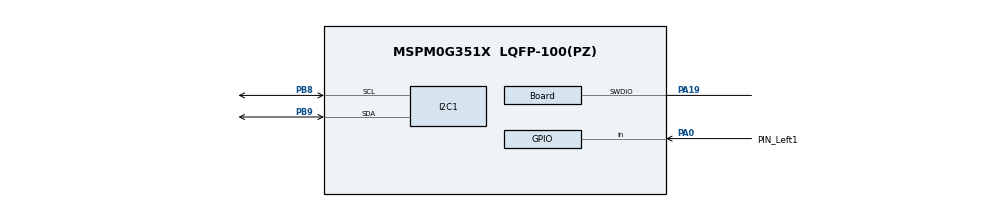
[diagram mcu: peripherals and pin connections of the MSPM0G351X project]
/**
 * @cliArgs --device "MSPM0G351X" --part "Default" --package "LQFP-100(PZ)" --product "mspm0_sdk@2.06.00.05"
 * @versions {"tool":"1.25.0+4268"}
 */

/**
 * Import the modules used in this configuration.
 */
const Board  = scripting.addModule("/ti/driverlib/Board");
const GPIO   = scripting.addModule("/ti/driverlib/GPIO", {}, false);
const GPIO1  = GPIO.addInstance();
const GPIO2  = GPIO.addInstance();
const I2C    = scripting.addModule("/ti/driverlib/I2C", {}, false);
const I2C1   = I2C.addInstance();
const PWM    = scripting.addModule("/ti/driverlib/PWM", {}, false);
const PWM1   = PWM.addInstance();
const QEI    = scripting.addModule("/ti/driverlib/QEI", {}, false);
const QEI1   = QEI.addInstance();
const QEI2   = QEI.addInstance();
const SYSCTL = scripting.addModule("/ti/driverlib/SYSCTL");
const TIMER  = scripting.addModule("/ti/driverlib/TIMER", {}, false);
const TIMER1 = TIMER.addInstance();
const TIMER2 = TIMER.addInstance();
const UART   = scripting.addModule("/ti/driverlib/UART", {}, false);
const UART1  = UART.addInstance();

/**
 * Write custom configuration values to the imported modules.
 */
Board.peripheral.swdioPin.$assign = "PA19";

GPIO1.$name                              = "GPIO_GraySensor";
GPIO1.port                               = "PORTA";
GPIO1.associatedPins.create(7);
GPIO1.associatedPins[0].$name            = "PIN_Left1";
GPIO1.associatedPins[0].direction        = "INPUT";
GPIO1.associatedPins[0].internalResistor = "PULL_DOWN";
GPIO1.associatedPins[0].pin.$assign      = "PA0";
GPIO1.associatedPins[1].$name            = "PIN_Left2";
GPIO1.associatedPins[1].internalResistor = "PULL_DOWN";
GPIO1.associatedPins[1].direction        = "INPUT";
GPIO1.associatedPins[2].$name            = "PIN_Left3";
GPIO1.associatedPins[2].internalResistor = "PULL_DOWN";
GPIO1.associatedPins[2].direction        = "INPUT";
GPIO1.associatedPins[3].$name            = "PIN_Left4";
GPIO1.associatedPins[3].internalResistor = "PULL_DOWN";
GPIO1.associatedPins[3].direction        = "INPUT";
GPIO1.associatedPins[4].$name            = "PIN_Left5";
GPIO1.associatedPins[4].direction        = "INPUT";
GPIO1.associatedPins[4].internalResistor = "PULL_DOWN";
GPIO1.associatedPins[5].$name            = "PIN_Left6";
GPIO1.associatedPins[5].direction        = "INPUT";
GPIO1.associatedPins[5].internalResistor = "PULL_DOWN";
GPIO1.associatedPins[6].$name            = "PIN_Left7";
GPIO1.associatedPins[6].direction        = "INPUT";
GPIO1.associatedPins[6].internalResistor = "PULL_DOWN";

GPIO2.$name                               = "GPIO_Soundsensor";
GPIO2.port                                = "PORTA";
GPIO2.associatedPins.create(2);
GPIO2.associatedPins[0].internalResistor  = "PULL_DOWN";
GPIO2.associatedPins[0].driveStrength     = "HIGH";
GPIO2.associatedPins[0].$name             = "Pin_Trig";
GPIO2.associatedPins[1].$name             = "PIN_Echo";
GPIO2.associatedPins[1].direction         = "INPUT";
GPIO2.associatedPins[1].internalResistor  = "PULL_DOWN";
GPIO2.associatedPins[1].polarity          = "RISE_FALL";
GPIO2.associatedPins[1].interruptPriority = "1";
GPIO2.associatedPins[1].interruptEn       = true;

I2C1.$name                             = "I2C_2";
I2C1.basicEnableController             = true;
I2C1.peripheral.sdaPin.$assign         = "PB9";
I2C1.peripheral.sclPin.$assign         = "PB8";
I2C1.sdaPinConfig.hideOutputInversion  = scripting.forceWrite(false);
I2C1.sdaPinConfig.onlyInternalResistor = scripting.forceWrite(false);
I2C1.sdaPinConfig.passedPeripheralType = scripting.forceWrite("Digital");
I2C1.sdaPinConfig.$name                = "ti_driverlib_gpio_GPIOPinGeneric4";
I2C1.sdaPinConfig.enableConfig         = true;
I2C1.sdaPinConfig.internalResistor     = "PULL_UP";
I2C1.sclPinConfig.hideOutputInversion  = scripting.forceWrite(false);
I2C1.sclPinConfig.onlyInternalResistor = scripting.forceWrite(false);
I2C1.sclPinConfig.passedPeripheralType = scripting.forceWrite("Digital");
I2C1.sclPinConfig.$name                = "ti_driverlib_gpio_GPIOPinGeneric5";
I2C1.sclPinConfig.enableConfig         = true;
I2C1.sclPinConfig.internalResistor     = "PULL_UP";

PWM1.$name                              = "PWM_Motor";
PWM1.clockDivider                       = 8;
PWM1.pwmMode                            = "EDGE_ALIGN_UP";
PWM1.timerStartTimer                    = true;
PWM1.ccIndex                            = [0,1,2,3];
PWM1.PWM_CHANNEL_0.$name                = "ti_driverlib_pwm_PWMTimerCC0";
PWM1.PWM_CHANNEL_0.shadowUpdateMode     = "COMP_DN_EVT";
PWM1.PWM_CHANNEL_1.$name                = "ti_driverlib_pwm_PWMTimerCC1";
PWM1.PWM_CHANNEL_1.shadowUpdateMode     = "COMP_DN_EVT";
PWM1.ccp0PinConfig.direction            = scripting.forceWrite("OUTPUT");
PWM1.ccp0PinConfig.hideOutputInversion  = scripting.forceWrite(false);
PWM1.ccp0PinConfig.onlyInternalResistor = scripting.forceWrite(false);
PWM1.ccp0PinConfig.passedPeripheralType = scripting.forceWrite("Digital");
PWM1.ccp0PinConfig.$name                = "ti_driverlib_gpio_GPIOPinGeneric0";
PWM1.ccp1PinConfig.direction            = scripting.forceWrite("OUTPUT");
PWM1.ccp1PinConfig.hideOutputInversion  = scripting.forceWrite(false);
PWM1.ccp1PinConfig.onlyInternalResistor = scripting.forceWrite(false);
PWM1.ccp1PinConfig.passedPeripheralType = scripting.forceWrite("Digital");
PWM1.ccp1PinConfig.$name                = "ti_driverlib_gpio_GPIOPinGeneric1";
PWM1.peripheral.$assign                 = "TIMA0";
PWM1.PWM_CHANNEL_2.$name                = "ti_driverlib_pwm_PWMTimerCC2";
PWM1.PWM_CHANNEL_3.$name                = "ti_driverlib_pwm_PWMTimerCC3";
PWM1.ccp2PinConfig.$name                = "ti_driverlib_gpio_GPIOPinGeneric2";
PWM1.ccp3PinConfig.$name                = "ti_driverlib_gpio_GPIOPinGeneric3";

QEI1.$name                              = "QEI_left";
QEI1.ccp0PinConfig.hideOutputInversion  = scripting.forceWrite(false);
QEI1.ccp0PinConfig.onlyInternalResistor = scripting.forceWrite(false);
QEI1.ccp0PinConfig.passedPeripheralType = scripting.forceWrite("Digital");
QEI1.ccp0PinConfig.$name                = "ti_driverlib_gpio_GPIOPinGeneric6";
QEI1.ccp1PinConfig.hideOutputInversion  = scripting.forceWrite(false);
QEI1.ccp1PinConfig.onlyInternalResistor = scripting.forceWrite(false);
QEI1.ccp1PinConfig.passedPeripheralType = scripting.forceWrite("Digital");
QEI1.ccp1PinConfig.$name                = "ti_driverlib_gpio_GPIOPinGeneric7";

QEI2.$name                              = "QEI_right";
QEI2.ccp0PinConfig.hideOutputInversion  = scripting.forceWrite(false);
QEI2.ccp0PinConfig.onlyInternalResistor = scripting.forceWrite(false);
QEI2.ccp0PinConfig.passedPeripheralType = scripting.forceWrite("Digital");
QEI2.ccp0PinConfig.$name                = "ti_driverlib_gpio_GPIOPinGeneric8";
QEI2.ccp1PinConfig.hideOutputInversion  = scripting.forceWrite(false);
QEI2.ccp1PinConfig.onlyInternalResistor = scripting.forceWrite(false);
QEI2.ccp1PinConfig.passedPeripheralType = scripting.forceWrite("Digital");
QEI2.ccp1PinConfig.$name                = "ti_driverlib_gpio_GPIOPinGeneric9";

SYSCTL.forceDefaultClkConfig = true;
SYSCTL.clockTreeEn           = true;

TIMER1.timerClkDiv      = 8;
TIMER1.timerClkPrescale = 4;
TIMER1.timerMode        = "ONE_SHOT_UP";
TIMER1.timerPeriod      = "65.50 ms";
TIMER1.$name            = "Timer_Sound";

TIMER2.$name             = "Timer_Track";
TIMER2.timerClkDiv       = 8;
TIMER2.timerClkPrescale  = 100;
TIMER2.timerMode         = "PERIODIC_UP";
TIMER2.timerPeriod       = "10 ms";
TIMER2.timerStartTimer   = true;
TIMER2.interrupts        = ["LOAD"];
TIMER2.interruptPriority = "1";

UART1.$name                            = "UART_BT";
UART1.enabledInterrupts                = ["RX"];
UART1.txPinConfig.$name                = "ti_driverlib_gpio_GPIOPinGeneric10";
UART1.txPinConfig.direction            = scripting.forceWrite("OUTPUT");
UART1.txPinConfig.hideOutputInversion  = scripting.forceWrite(false);
UART1.txPinConfig.onlyInternalResistor = scripting.forceWrite(false);
UART1.txPinConfig.passedPeripheralType = scripting.forceWrite("Digital");
UART1.rxPinConfig.$name                = "ti_driverlib_gpio_GPIOPinGeneric11";
UART1.rxPinConfig.hideOutputInversion  = scripting.forceWrite(false);
UART1.rxPinConfig.onlyInternalResistor = scripting.forceWrite(false);
UART1.rxPinConfig.passedPeripheralType = scripting.forceWrite("Digital");

/**
 * Pinmux solution for unlocked pins/peripherals. This ensures that minor changes to the automatic solver in a future
 * version of the tool will not impact the pinmux you originally saw.  These lines can be completely deleted in order to
 * re-solve from scratch.
 */
Board.peripheral.$suggestSolution            = "DEBUGSS";
Board.peripheral.swclkPin.$suggestSolution   = "PA20";
GPIO1.associatedPins[1].pin.$suggestSolution = "PA6";
GPIO1.associatedPins[2].pin.$suggestSolution = "PA5";
GPIO1.associatedPins[3].pin.$suggestSolution = "PA4";
GPIO1.associatedPins[4].pin.$suggestSolution = "PA31";
GPIO1.associatedPins[5].pin.$suggestSolution = "PA30";
GPIO1.associatedPins[6].pin.$suggestSolution = "PA29";
GPIO2.associatedPins[0].pin.$suggestSolution = "PA9";
GPIO2.associatedPins[1].pin.$suggestSolution = "PA28";
I2C1.peripheral.$suggestSolution             = "I2C2";
PWM1.peripheral.ccp0Pin.$suggestSolution     = "PA21";
PWM1.peripheral.ccp1Pin.$suggestSolution     = "PA22";
PWM1.peripheral.ccp2Pin.$suggestSolution     = "PA15";
PWM1.peripheral.ccp3Pin.$suggestSolution     = "PA12";
QEI1.peripheral.$suggestSolution             = "TIMG9";
QEI1.peripheral.ccp0Pin.$suggestSolution     = "PA3";
QEI1.peripheral.ccp1Pin.$suggestSolution     = "PA2";
QEI2.peripheral.$suggestSolution             = "TIMG8";
QEI2.peripheral.ccp0Pin.$suggestSolution     = "PA17";
QEI2.peripheral.ccp1Pin.$suggestSolution     = "PA18";
TIMER1.peripheral.$suggestSolution           = "TIMG0";
TIMER2.peripheral.$suggestSolution           = "TIMA1";
UART1.peripheral.$suggestSolution            = "UART0";
UART1.peripheral.rxPin.$suggestSolution      = "PA1";
UART1.peripheral.txPin.$suggestSolution      = "PA10";
